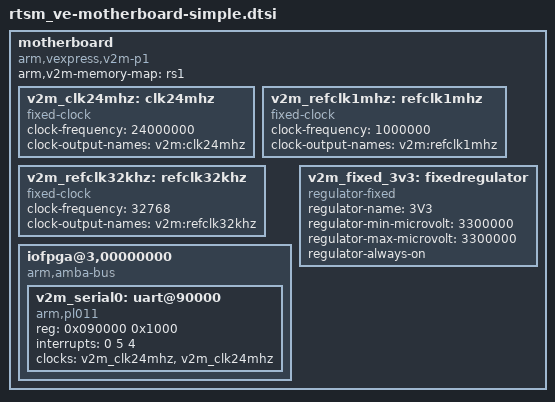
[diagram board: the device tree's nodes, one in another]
/*
 * Copyright (c) 2013-2018, ARM Limited and Contributors. All rights reserved.
 *
 * SPDX-License-Identifier: BSD-3-Clause
 */

	motherboard {
		arm,v2m-memory-map = "rs1";
		compatible = "arm,vexpress,v2m-p1", "simple-bus";
		#address-cells = <2>; /* SMB chipselect number and offset */
		#size-cells = <1>;
		ranges;

		v2m_clk24mhz: clk24mhz {
			compatible = "fixed-clock";
			#clock-cells = <0>;
			clock-frequency = <24000000>;
			clock-output-names = "v2m:clk24mhz";
		};

		v2m_refclk1mhz: refclk1mhz {
			compatible = "fixed-clock";
			#clock-cells = <0>;
			clock-frequency = <1000000>;
			clock-output-names = "v2m:refclk1mhz";
		};

		v2m_refclk32khz: refclk32khz {
			compatible = "fixed-clock";
			#clock-cells = <0>;
			clock-frequency = <32768>;
			clock-output-names = "v2m:refclk32khz";
		};

		iofpga@3,00000000 {
			compatible = "arm,amba-bus", "simple-bus";
			#address-cells = <1>;
			#size-cells = <1>;
			ranges = <0 3 0 0x200000>;

			v2m_serial0: uart@90000 {
				compatible = "arm,pl011", "arm,primecell";
				reg = <0x090000 0x1000>;
				interrupts = <0 5 4>;
				clocks = <&v2m_clk24mhz>, <&v2m_clk24mhz>;
				clock-names = "uartclk", "apb_pclk";
			};

		};

		v2m_fixed_3v3: fixedregulator {
			compatible = "regulator-fixed";
			regulator-name = "3V3";
			regulator-min-microvolt = <3300000>;
			regulator-max-microvolt = <3300000>;
			regulator-always-on;
		};

	};
